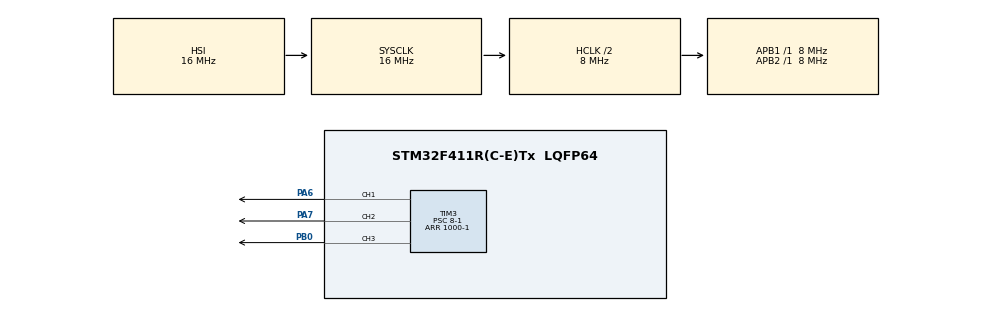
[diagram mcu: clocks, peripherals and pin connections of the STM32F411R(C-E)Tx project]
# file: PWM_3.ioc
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Mcu.Family=STM32F4
Mcu.Name=STM32F411R(C-E)Tx
Mcu.Package=LQFP64
NVIC.PriorityGroup=NVIC_PRIORITYGROUP_0
PA13.Mode=Serial_Wire
PA13.Signal=SYS_JTMS-SWDIO
PA14.Mode=Serial_Wire
PA14.Signal=SYS_JTCK-SWCLK
PA6.Signal=S_TIM3_CH1
PA7.Signal=S_TIM3_CH2
PB0.Signal=S_TIM3_CH3
ProjectManager.HeapSize=0x200
ProjectManager.StackSize=0x400
ProjectManager.TargetToolchain=STM32CubeIDE
RCC.48MHZClocksFreq_Value=84000000
RCC.AHBCLKDivider=RCC_SYSCLK_DIV2
RCC.AHBFreq_Value=8000000
RCC.APB1Freq_Value=8000000
RCC.APB1TimFreq_Value=8000000
RCC.APB2Freq_Value=8000000
RCC.APB2TimFreq_Value=8000000
RCC.CortexFreq_Value=8000000
RCC.FLatency-AdvancedSettings=FLASH_LATENCY_0
RCC.HCLKFreq_Value=8000000
RCC.HSE_VALUE=8000000
RCC.HSI_VALUE=16000000
RCC.PLLN=336
RCC.PLLP=RCC_PLLP_DIV4
RCC.SYSCLKFreq_VALUE=16000000
RCC.VCOOutputFreq_Value=336000000
SH.S_TIM3_CH1.0=TIM3_CH1,PWM Generation1 CH1
SH.S_TIM3_CH2.0=TIM3_CH2,PWM Generation2 CH2
SH.S_TIM3_CH3.0=TIM3_CH3,PWM Generation3 CH3
TIM3.Channel-PWM\ Generation1\ CH1=TIM_CHANNEL_1
TIM3.Channel-PWM\ Generation2\ CH2=TIM_CHANNEL_2
TIM3.Channel-PWM\ Generation3\ CH3=TIM_CHANNEL_3
TIM3.Period=1000-1
TIM3.Prescaler=8-1
TIM3.Pulse-PWM\ Generation1\ CH1=250
VP_TIM3_VS_ClockSourceINT.Mode=Internal
board=NUCLEO-F411RE

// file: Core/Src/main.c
/* USER CODE BEGIN Header */
/**
  ******************************************************************************
  * @file           : main.c
  * @brief          : Main program body
  ******************************************************************************
  * @attention
  *
  * Copyright (c) 2023 STMicroelectronics.
  * All rights reserved.
  * Este ejercicio tambien se tomo de los videos de calibeta, direccion
  * https://www.youtube.com/watch?v=MrwDeviHgnc&ab_channel=CaliBeta
  * Aqui estamos haciendo un barrido en el PWM del 25% al 100%
  * This software is licensed under terms that can be found in the LICENSE file
  * in the root directory of this software component.
  * If no LICENSE file comes with this software, it is provided AS-IS.
  *
  ******************************************************************************
  */
/* USER CODE END Header */
#include "main.h"

TIM_HandleTypeDef htim3;

/* USER CODE BEGIN PV */
uint16_t CicloUtil = 0;
uint16_t CicloUtilMax = 0;
/* USER CODE END PV */

void SystemClock_Config(void);
static void MX_GPIO_Init(void);
static void MX_TIM3_Init(void);

int main(void)
{

  /* MCU Configuration--------------------------------------------------------*/

  /* Reset of all peripherals, Initializes the Flash interface and the Systick. */
  HAL_Init();

  /* Configure the system clock */
  SystemClock_Config();

  /* Initialize all configured peripherals */
  MX_GPIO_Init();
  MX_TIM3_Init();
  /* USER CODE BEGIN 2 */
  HAL_TIM_PWM_Start(&htim3, TIM_CHANNEL_1);
  CicloUtilMax = htim3.Instance->ARR; //si hacemos CicloUtil=600 el PWM barre hasta el 60%
  /* USER CODE END 2 */

  /* Infinite loop */
  while (1)
  {

    /* USER CODE BEGIN 3 */
	  for(CicloUtil=0; CicloUtil < CicloUtilMax; ++CicloUtil)
	  {
		  htim3.Instance->CCR1 = CicloUtil;
		  HAL_Delay(1);
	  }
  }
  /* USER CODE END 3 */
}

void SystemClock_Config(void)
{
  RCC_OscInitTypeDef RCC_OscInitStruct = {0};
  RCC_ClkInitTypeDef RCC_ClkInitStruct = {0};

  /** Configure the main internal regulator output voltage
  */
  __HAL_RCC_PWR_CLK_ENABLE();
  __HAL_PWR_VOLTAGESCALING_CONFIG(PWR_REGULATOR_VOLTAGE_SCALE1);

  /** Initializes the RCC Oscillators according to the specified parameters
  * in the RCC_OscInitTypeDef structure.
  */
  RCC_OscInitStruct.OscillatorType = RCC_OSCILLATORTYPE_HSI;
  RCC_OscInitStruct.HSIState = RCC_HSI_ON;
  RCC_OscInitStruct.HSICalibrationValue = RCC_HSICALIBRATION_DEFAULT;
  RCC_OscInitStruct.PLL.PLLState = RCC_PLL_NONE;
  if (HAL_RCC_OscConfig(&RCC_OscInitStruct) != HAL_OK)
  {
    Error_Handler();
  }

  /** Initializes the CPU, AHB and APB buses clocks
  */
  RCC_ClkInitStruct.ClockType = RCC_CLOCKTYPE_HCLK|RCC_CLOCKTYPE_SYSCLK
                              |RCC_CLOCKTYPE_PCLK1|RCC_CLOCKTYPE_PCLK2;
  RCC_ClkInitStruct.SYSCLKSource = RCC_SYSCLKSOURCE_HSI;
  RCC_ClkInitStruct.AHBCLKDivider = RCC_SYSCLK_DIV2;
  RCC_ClkInitStruct.APB1CLKDivider = RCC_HCLK_DIV1;
  RCC_ClkInitStruct.APB2CLKDivider = RCC_HCLK_DIV1;

  if (HAL_RCC_ClockConfig(&RCC_ClkInitStruct, FLASH_LATENCY_0) != HAL_OK)
  {
    Error_Handler();
  }
}

static void MX_TIM3_Init(void)
{

  TIM_ClockConfigTypeDef sClockSourceConfig = {0};
  TIM_MasterConfigTypeDef sMasterConfig = {0};
  TIM_OC_InitTypeDef sConfigOC = {0};

  htim3.Instance = TIM3;
  htim3.Init.Prescaler = 8-1;
  htim3.Init.CounterMode = TIM_COUNTERMODE_UP;
  htim3.Init.Period = 1000-1;
  htim3.Init.ClockDivision = TIM_CLOCKDIVISION_DIV1;
  htim3.Init.AutoReloadPreload = TIM_AUTORELOAD_PRELOAD_DISABLE;
  if (HAL_TIM_Base_Init(&htim3) != HAL_OK)
  {
    Error_Handler();
  }
  sClockSourceConfig.ClockSource = TIM_CLOCKSOURCE_INTERNAL;
  if (HAL_TIM_ConfigClockSource(&htim3, &sClockSourceConfig) != HAL_OK)
  {
    Error_Handler();
  }
  if (HAL_TIM_PWM_Init(&htim3) != HAL_OK)
  {
    Error_Handler();
  }
  sMasterConfig.MasterOutputTrigger = TIM_TRGO_RESET;
  sMasterConfig.MasterSlaveMode = TIM_MASTERSLAVEMODE_DISABLE;
  if (HAL_TIMEx_MasterConfigSynchronization(&htim3, &sMasterConfig) != HAL_OK)
  {
    Error_Handler();
  }
  sConfigOC.OCMode = TIM_OCMODE_PWM1;
  sConfigOC.Pulse = 250;
  sConfigOC.OCPolarity = TIM_OCPOLARITY_HIGH;
  sConfigOC.OCFastMode = TIM_OCFAST_DISABLE;
  if (HAL_TIM_PWM_ConfigChannel(&htim3, &sConfigOC, TIM_CHANNEL_1) != HAL_OK)
  {
    Error_Handler();
  }
  sConfigOC.Pulse = 0;
  if (HAL_TIM_PWM_ConfigChannel(&htim3, &sConfigOC, TIM_CHANNEL_2) != HAL_OK)
  {
    Error_Handler();
  }
  if (HAL_TIM_PWM_ConfigChannel(&htim3, &sConfigOC, TIM_CHANNEL_3) != HAL_OK)
  {
    Error_Handler();
  }
  HAL_TIM_MspPostInit(&htim3);

}

static void MX_GPIO_Init(void)
{

  /* GPIO Ports Clock Enable */
  __HAL_RCC_GPIOA_CLK_ENABLE();
  __HAL_RCC_GPIOB_CLK_ENABLE();

}

void Error_Handler(void)
{
  __disable_irq();
  while (1)
  {
  }
}
